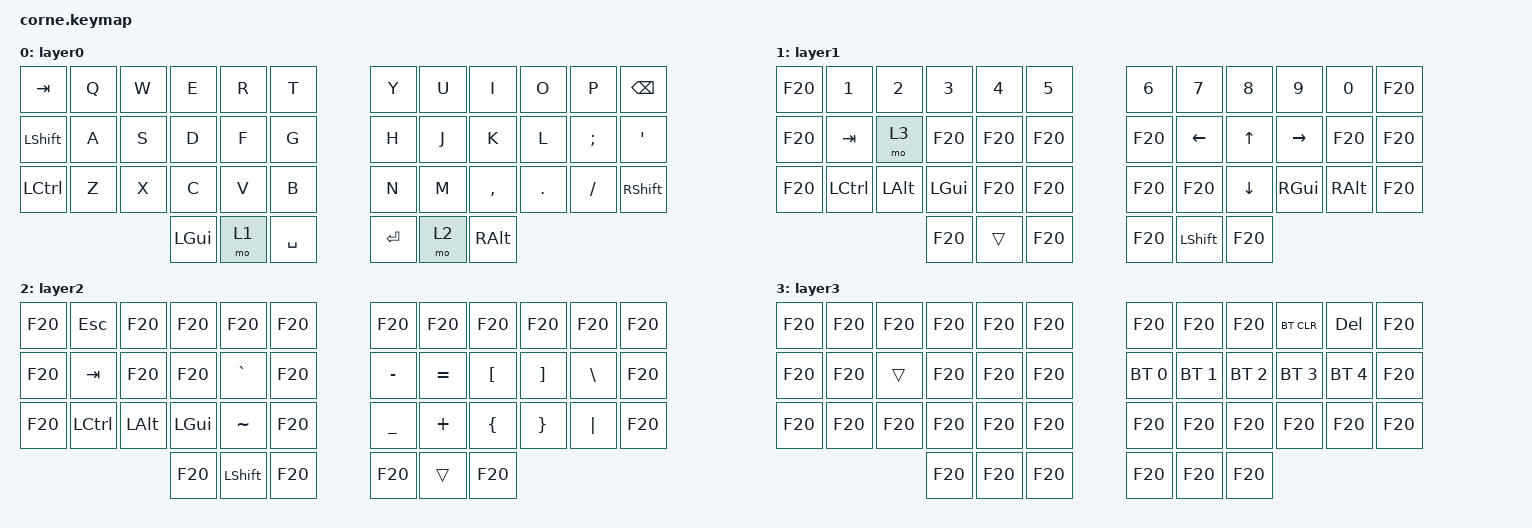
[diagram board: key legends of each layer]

  /*
  * Copyright (c) 2020 The ZMK Contributors
  *
  * SPDX-License-Identifier: MIT
  */

  #include <behaviors.dtsi>
  #include <dt-bindings/zmk/keys.h>
  #include <dt-bindings/zmk/bt.h>
  #include <dt-bindings/zmk/ext_power.h>

  / {
    keymap {
      compatible = "zmk,keymap";
  layer0 {
          bindings = <
          &kp TAB &kp Q &kp W &kp E &kp R &kp T &kp Y &kp U &kp I &kp O &kp P &kp BACKSPACE &kp LEFT_SHIFT &kp A &kp S &kp D &kp F &kp G &kp H &kp J &kp K &kp L &kp SEMICOLON &kp SINGLE_QUOTE &kp LEFT_CONTROL &kp Z &kp X &kp C &kp V &kp B &kp N &kp M &kp COMMA &kp DOT &kp SLASH &kp RIGHT_SHIFT &kp LEFT_GUI &mo 1 &kp SPACE &kp ENTER &mo 2 &kp RIGHT_ALT
          >;
        };layer1 {
          bindings = <
          &kp F20 &kp N1 &kp N2 &kp N3 &kp N4 &kp N5 &kp N6 &kp N7 &kp N8 &kp N9 &kp N0 &kp F20 &kp F20 &kp TAB &mo 3 &kp F20 &kp F20 &kp F20 &kp F20 &kp LEFT &kp UP &kp RIGHT &kp F20 &kp F20 &kp F20 &kp LEFT_CONTROL &kp LEFT_ALT &kp LEFT_GUI &kp F20 &kp F20 &kp F20 &kp F20 &kp DOWN &kp RIGHT_GUI &kp RIGHT_ALT &kp F20 &kp F20 &trans &kp F20 &kp F20 &kp LEFT_SHIFT &kp F20
          >;
        };layer2 {
          bindings = <
&kp F20 &kp ESCAPE &kp F20 &kp F20 &kp F20 &kp F20 &kp F20 &kp F20 &kp F20 &kp F20 &kp F20 &kp F20 &kp F20 &kp TAB &kp F20 &kp F20 &kp GRAVE &kp F20 &kp MINUS &kp EQUAL &kp LEFT_BRACKET &kp RIGHT_BRACKET &kp BACKSLASH &kp F20 &kp F20 &kp LEFT_CONTROL &kp LEFT_ALT &kp LEFT_GUI &kp TILDE &kp F20 &kp UNDERSCORE &kp PLUS &kp LBRC &kp RBRC &kp PIPE &kp F20 &kp F20 &kp LEFT_SHIFT &kp F20 &kp F20 &trans &kp F20
          >;
        };layer3 {
          bindings = <
          &kp F20 &kp F20 &kp F20 &kp F20 &kp F20 &kp F20    &kp F20 &kp F20 &kp F20 &bt BT_CLR &kp DELETE &kp F20
           &kp F20 &kp F20 &trans &kp F20 &kp F20 &kp F20    &bt BT_SEL 0 &bt BT_SEL 1 &bt BT_SEL 2 &bt BT_SEL 3 &bt BT_SEL 4 &kp F20
          &kp F20 &kp F20 &kp F20 &kp F20 &kp F20 &kp F20    &kp F20 &kp F20 &kp F20 &kp F20 &kp F20 &kp F20
                                  &kp F20 &kp F20 &kp F20    &kp F20 &kp F20 &kp F20
          >;
        };
    };
  };
  
